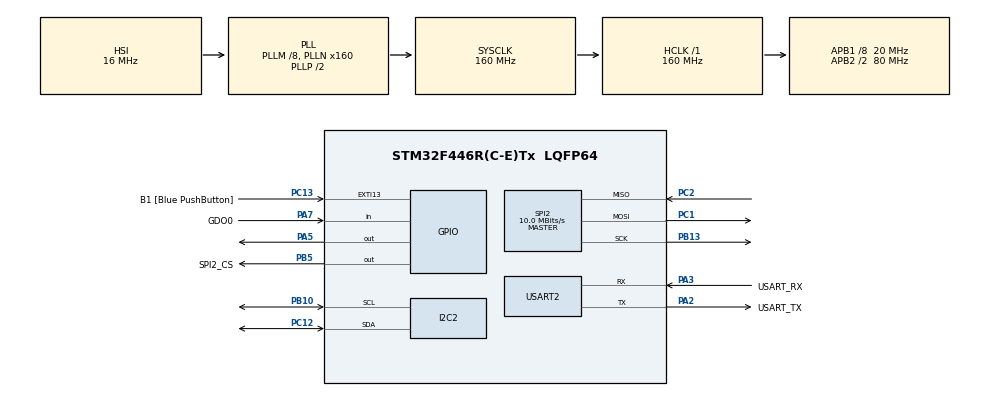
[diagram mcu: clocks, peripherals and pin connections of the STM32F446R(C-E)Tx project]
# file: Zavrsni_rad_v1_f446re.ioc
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Mcu.Family=STM32F4
Mcu.Name=STM32F446R(C-E)Tx
Mcu.Package=LQFP64
NVIC.PriorityGroup=NVIC_PRIORITYGROUP_0
NVIC.TIM6_DAC_IRQn=true\:0\:0\:false\:false\:true\:false\:true\:true
NVIC.TimeBase=TIM6_DAC_IRQn
NVIC.TimeBaseIP=TIM6
PA13.GPIO_Label=TMS
PA13.Mode=Serial_Wire
PA13.Signal=SYS_JTMS-SWDIO
PA14.GPIO_Label=TCK
PA14.Mode=Serial_Wire
PA14.Signal=SYS_JTCK-SWCLK
PA2.GPIO_Label=USART_TX
PA2.Mode=Asynchronous
PA2.Signal=USART2_TX
PA3.GPIO_Label=USART_RX
PA3.Mode=Asynchronous
PA3.Signal=USART2_RX
PA5.Signal=GPIO_Output
PA7.GPIO_Label=GDO0
PA7.Signal=GPIO_Input
PB10.GPIO_Pu=GPIO_PULLUP
PB10.Mode=I2C
PB10.Signal=I2C2_SCL
PB13.Mode=Full_Duplex_Master
PB13.Signal=SPI2_SCK
PB3.GPIO_Label=SWO
PB3.Signal=SYS_JTDO-SWO
PB5.GPIO_Label=SPI2_CS
PB5.PinState=GPIO_PIN_SET
PB5.Signal=GPIO_Output
PC1.Mode=Full_Duplex_Master
PC1.Signal=SPI2_MOSI
PC12.GPIO_Pu=GPIO_PULLUP
PC12.Mode=I2C
PC12.Signal=I2C2_SDA
PC13.GPIO_Label=B1 [Blue PushButton]
PC13.GPIO_ModeDefaultEXTI=GPIO_MODE_IT_FALLING
PC13.Signal=GPXTI13
PC14-OSC32_IN.Mode=LSE-External-Oscillator
PC14-OSC32_IN.Signal=RCC_OSC32_IN
PC15-OSC32_OUT.Mode=LSE-External-Oscillator
PC15-OSC32_OUT.Signal=RCC_OSC32_OUT
PC2.Mode=Full_Duplex_Master
PC2.Signal=SPI2_MISO
PH0-OSC_IN.Mode=HSE-External-Oscillator
PH0-OSC_IN.Signal=RCC_OSC_IN
PH1-OSC_OUT.Mode=HSE-External-Oscillator
PH1-OSC_OUT.Signal=RCC_OSC_OUT
ProjectManager.HeapSize=0x200
ProjectManager.StackSize=0x400
ProjectManager.TargetToolchain=STM32CubeIDE
RCC.48MHZClocksFreq_Value=84000000
RCC.AHBFreq_Value=160000000
RCC.APB1CLKDivider=RCC_HCLK_DIV8
RCC.APB1Freq_Value=20000000
RCC.APB1TimFreq_Value=40000000
RCC.APB2CLKDivider=RCC_HCLK_DIV2
RCC.APB2Freq_Value=80000000
RCC.APB2TimFreq_Value=160000000
RCC.CortexFreq_Value=160000000
RCC.FLatency-AdvancedSettings=FLASH_LATENCY_5
RCC.HCLKFreq_Value=160000000
RCC.HSE_VALUE=8000000
RCC.HSI_VALUE=16000000
RCC.PLLM=8
RCC.PLLN=160
RCC.SYSCLKFreq_VALUE=160000000
RCC.SYSCLKSource=RCC_SYSCLKSOURCE_PLLCLK
RCC.USBFreq_Value=160000000
RCC.VCOOutputFreq_Value=320000000
SPI2.BaudRatePrescaler=SPI_BAUDRATEPRESCALER_2
SPI2.CalculateBaudRate=10.0 MBits/s
SPI2.Direction=SPI_DIRECTION_2LINES
SPI2.Mode=SPI_MODE_MASTER
SPI2.VirtualType=VM_MASTER
TIM1.Prescaler=0
TIM2.Prescaler=39
USART2.VirtualMode=VM_ASYNC
VP_SYS_VS_tim6.Mode=TIM6
VP_TIM1_VS_ClockSourceINT.Mode=Internal
VP_TIM2_VS_ClockSourceINT.Mode=Internal
board=NUCLEO-F446RE

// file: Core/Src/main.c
/* USER CODE BEGIN Header */
/**
  ******************************************************************************
  * @file           : main.c
  * @brief          : Main program body
  ******************************************************************************
  * @attention
  *
  * Copyright (c) 2024 STMicroelectronics.
  * All rights reserved.
  *
  * This software is licensed under terms that can be found in the LICENSE file
  * in the root directory of this software component.
  * If no LICENSE file comes with this software, it is provided AS-IS.
  *
  ******************************************************************************
  */
/* USER CODE END Header */
#include "main.h"
#include "i2c.h"
#include "spi.h"
#include "tim.h"
#include "usart.h"
#include "gpio.h"

/* USER CODE BEGIN Includes */
#include "LCD1602.h"
#include "CC1101_E07_M1101D_SMA.h"
#include <string.h>
#include <stdio.h>
/* USER CODE END Includes */

void SystemClock_Config(void);

int main(void)
{

  /* MCU Configuration--------------------------------------------------------*/

  /* Reset of all peripherals, Initializes the Flash interface and the Systick. */
  HAL_Init();

  /* Configure the system clock */
  SystemClock_Config();

  /* Initialize all configured peripherals */
  MX_GPIO_Init();
  MX_SPI2_Init();
  MX_TIM1_Init();
  MX_USART2_UART_Init();
  MX_TIM2_Init();
  MX_I2C2_Init();
  /* USER CODE BEGIN 2 */
  HAL_TIM_Base_Start(&htim1);
  HAL_TIM_Base_Start(&htim2);

//  uint8_t cnt = 0;
  uint8_t rxData[64];
  uint8_t status = 0x77;
  uint8_t RXBytesStatus;
  uint8_t numRXbytes;
  char serialStatus[50];
//  char aTxBuffer[] = "ovdje1\r\n";
//  HAL_UART_Transmit(&huart2, (uint8_t*)aTxBuffer, strlen(aTxBuffer), HAL_MAX_DELAY);
//  manual_POR();
//  cc1101_init(0);
  HD44780_Init(2);

//  status = command_strobe(SNOP);
  snprintf(serialStatus, sizeof(serialStatus), "0x%02X\r\n", status);
  HAL_UART_Transmit(&huart2, (uint8_t*)serialStatus, strlen(serialStatus), HAL_MAX_DELAY);
  /* USER CODE END 2 */

  /* Infinite loop */
  /* USER CODE BEGIN WHILE */
  while (1)
  {
//	  char aTxBuffer[32];
//	  HAL_UART_Transmit(&huart2, (uint8_t*)aTxBuffer, strlen(aTxBuffer), HAL_MAX_DELAY);
//	  HD44780_Clear();
//	  HD44780_NoDisplay();
//	  HD44780_Cursor();
//	  HD44780_SetCursor(0,0);
//	  HD44780_PrintStr("Dobrodosli doma. ");
//	  HD44780_Display();
//	  HAL_Delay(1000);
//	  RXBytesStatus = read_status_reg(RXBYTES, &status);
//	  snprintf(serialStatus, sizeof(serialStatus), "RXBYTES_before: 0x%02X\r\n", RXBytesStatus);
//	  HAL_UART_Transmit(&huart2, (uint8_t*)serialStatus, strlen(serialStatus), HAL_MAX_DELAY);
//	  delay_us(1000);
//	  delay_us(100);
//	  delay_us(40);
//	  delay_us(10);
//	  delay_us(1);
//	  HAL_Delay(1000);
//
//	  RXBytesStatus = read_single_byte(ADDR, &status);
//	  snprintf(serialStatus, sizeof(serialStatus), "RXBYTES_before: 0x%02X\r\n", RXBytesStatus);
//	  HAL_UART_Transmit(&huart2, (uint8_t*)serialStatus, strlen(serialStatus), HAL_MAX_DELAY);
//
//	  for(int i=0; i < 64; i++)
//	  {
//		  rxData[i]=0;
//	  }
//
//	  numRXbytes = receive_burst_byte_433(rxData);
//
//	  for(int i=0; i < 64; i++)
//	  {
//		  sprintf(serialStatus, "RXDATA[%d]: 0x%02X\r\n", i,rxData[i]);
//		  HAL_UART_Transmit(&huart2, (uint8_t*)serialStatus, strlen(serialStatus), HAL_MAX_DELAY);
//	  }
//
//	  RXBytesStatus = read_status_reg(RXBYTES, &status);
//	  snprintf(serialStatus, sizeof(serialStatus), "RXBYTES_after: 0x%02X\r\n", RXBytesStatus);
//	  HAL_UART_Transmit(&huart2, (uint8_t*)serialStatus, strlen(serialStatus), HAL_MAX_DELAY);

    /* USER CODE END WHILE */

  }
}

void SystemClock_Config(void)
{
  RCC_OscInitTypeDef RCC_OscInitStruct = {0};
  RCC_ClkInitTypeDef RCC_ClkInitStruct = {0};

  /** Configure the main internal regulator output voltage
  */
  __HAL_RCC_PWR_CLK_ENABLE();
  __HAL_PWR_VOLTAGESCALING_CONFIG(PWR_REGULATOR_VOLTAGE_SCALE1);

  /** Initializes the RCC Oscillators according to the specified parameters
  * in the RCC_OscInitTypeDef structure.
  */
  RCC_OscInitStruct.OscillatorType = RCC_OSCILLATORTYPE_HSI;
  RCC_OscInitStruct.HSIState = RCC_HSI_ON;
  RCC_OscInitStruct.HSICalibrationValue = RCC_HSICALIBRATION_DEFAULT;
  RCC_OscInitStruct.PLL.PLLState = RCC_PLL_ON;
  RCC_OscInitStruct.PLL.PLLSource = RCC_PLLSOURCE_HSI;
  RCC_OscInitStruct.PLL.PLLM = 8;
  RCC_OscInitStruct.PLL.PLLN = 160;
  RCC_OscInitStruct.PLL.PLLP = RCC_PLLP_DIV2;
  RCC_OscInitStruct.PLL.PLLQ = 2;
  RCC_OscInitStruct.PLL.PLLR = 2;
  if (HAL_RCC_OscConfig(&RCC_OscInitStruct) != HAL_OK)
  {
    Error_Handler();
  }

  /** Initializes the CPU, AHB and APB buses clocks
  */
  RCC_ClkInitStruct.ClockType = RCC_CLOCKTYPE_HCLK|RCC_CLOCKTYPE_SYSCLK
                              |RCC_CLOCKTYPE_PCLK1|RCC_CLOCKTYPE_PCLK2;
  RCC_ClkInitStruct.SYSCLKSource = RCC_SYSCLKSOURCE_PLLCLK;
  RCC_ClkInitStruct.AHBCLKDivider = RCC_SYSCLK_DIV1;
  RCC_ClkInitStruct.APB1CLKDivider = RCC_HCLK_DIV8;
  RCC_ClkInitStruct.APB2CLKDivider = RCC_HCLK_DIV2;

  if (HAL_RCC_ClockConfig(&RCC_ClkInitStruct, FLASH_LATENCY_5) != HAL_OK)
  {
    Error_Handler();
  }
}

void HAL_TIM_PeriodElapsedCallback(TIM_HandleTypeDef *htim)
{
  if (htim->Instance == TIM6) {
    HAL_IncTick();
  }
}

void Error_Handler(void)
{
  __disable_irq();
  while (1)
  {
  }
}
